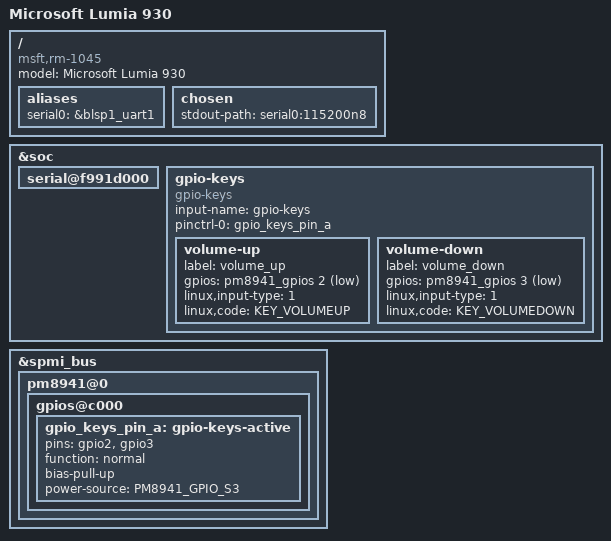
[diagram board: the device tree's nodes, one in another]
// SPDX-License-Identifier: GPL-2.0
#include "qcom-msm8974.dtsi"
#include "qcom-pm8841.dtsi"
#include "qcom-pm8941.dtsi"
#include <dt-bindings/gpio/gpio.h>
#include <dt-bindings/input/input.h>
#include <dt-bindings/pinctrl/qcom,pmic-gpio.h>

/ {
    model = "Microsoft Lumia 930";
    compatible = "msft,rm-1045", "qcom,msm8974";

    aliases {
        serial0 = &blsp1_uart1;
    }

    chosen {
		stdout-path = "serial0:115200n8";
	};   
};

&soc {
	serial@f991d000 {
		status = "ok";
	};

	gpio-keys {
		compatible = "gpio-keys";
		input-name = "gpio-keys";

		pinctrl-names = "default";
		pinctrl-0 = <&gpio_keys_pin_a>;

		volume-up {
			label = "volume_up";
			gpios = <&pm8941_gpios 2 GPIO_ACTIVE_LOW>;
			linux,input-type = <1>;
			linux,code = <KEY_VOLUMEUP>;
		};

		volume-down {
			label = "volume_down";
			gpios = <&pm8941_gpios 3 GPIO_ACTIVE_LOW>;
			linux,input-type = <1>;
			linux,code = <KEY_VOLUMEDOWN>;
		};
	};
};

&spmi_bus {
	pm8941@0 {
		gpios@c000 {
			gpio_keys_pin_a: gpio-keys-active {
				pins = "gpio2", "gpio3";
				function = "normal";

				bias-pull-up;
				power-source = <PM8941_GPIO_S3>;
			};
		};
	};
};
